# CC2756 register map
File version: 1.0
CPU: CM4 r0p4, little endian, no MPU, no FPU, VTOR, 3 interrupt priority bits
Registers are 32-bit, read-write, reset 0x0 unless marked. A register's access mark holds for its fields unless they carry their own. Offsets are from the block's base; [hi:lo] are bit positions; {n}, {i} and the like mark numbered series; 'fields as' and 'values as' point back to an identical list.

## LRFDRFE (part 2 of 2)
Base 0x40083000
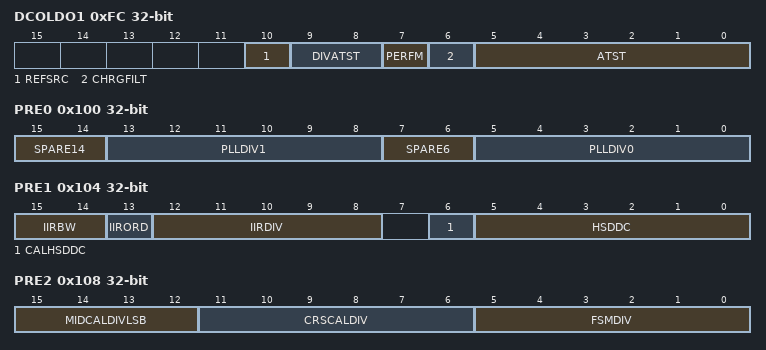
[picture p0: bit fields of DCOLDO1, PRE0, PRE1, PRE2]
0xFC DCOLDO1 — Internal. Only to be used through TI provided API.
  [10] REFSRC — Internal. Only to be used through TI provided API.
    1=BAW (Internal. Only to be used through TI provided API.); 0=XTAL (Internal. Only to be used through TI provided API.)
  [9:8] DIVATST — Internal. Only to be used through TI provided API.
    3=ONES (Internal. Only to be used through TI provided API.); 0=ZEROS (Internal. Only to be used through TI provided API.)
  [7] PERFM — Internal. Only to be used through TI provided API.
    1=EN (Internal. Only to be used through TI provided API.); 0=DIS (Internal. Only to be used through TI provided API.)
  [6] CHRGFILT — Internal. Only to be used through TI provided API.
    values as PERFM
  [5:0] ATST — Internal. Only to be used through TI provided API.
    32=VSSANA (Internal. Only to be used through TI provided API.); 1=FIRST_OUT (Internal. Only to be used through TI provided API.); 0=LDO_OUT (Internal. Only to be used through TI provided API.)
0x100 PRE0 — Internal. Only to be used through TI provided API.
  [15:14] SPARE14 — Internal. Only to be used through TI provided API.
    3=ALLONES (Internal. Only to be used through TI provided API.); 0=ALLZEROS (Internal. Only to be used through TI provided API.)
  [13:8] PLLDIV1 — Internal. Only to be used through TI provided API.
    63=ALLONES (Internal. Only to be used through TI provided API.); 0=ALLZEROS (Internal. Only to be used through TI provided API.)
  [7:6] SPARE6 — Internal. Only to be used through TI provided API.
    values as SPARE14
  [5:0] PLLDIV0 — Internal. Only to be used through TI provided API.
    values as PLLDIV1
0x104 PRE1 — Internal. Only to be used through TI provided API.
  [15:14] IIRBW — Internal. Only to be used through TI provided API.
    3=K16 (Internal. Only to be used through TI provided API.); 2=K8 (Internal. Only to be used through TI provided API.); 1=K4 (Internal. Only to be used through TI provided API.); 0=K2 (Internal. Only to be used through TI provided API.)
  [13] IIRORD — Internal. Only to be used through TI provided API.
    1=SECOND (Internal. Only to be used through TI provided API.); 0=FIRST (Internal. Only to be used through TI provided API.)
  [12:8] IIRDIV — Internal. Only to be used through TI provided API.
    31=ALLONES (Internal. Only to be used through TI provided API.); 0=ALLZEROS (Internal. Only to be used through TI provided API.)
  [6] CALHSDDC — Internal. Only to be used through TI provided API.
    1=GATE (Internal. Only to be used through TI provided API.); 0=NOGATE (Internal. Only to be used through TI provided API.)
  [5:0] HSDDC — Internal. Only to be used through TI provided API.
    values as PRE0.PLLDIV1
0x108 PRE2 — Internal. Only to be used through TI provided API.
  [15:12] MIDCALDIVLSB — Internal. Only to be used through TI provided API.
    15=ALLONES (Internal. Only to be used through TI provided API.); 0=ALLZEROS (Internal. Only to be used through TI provided API.)
  [11:6] CRSCALDIV — Internal. Only to be used through TI provided API.
    values as PRE0.PLLDIV1
  [5:0] FSMDIV — Internal. Only to be used through TI provided API.
    values as PRE0.PLLDIV1
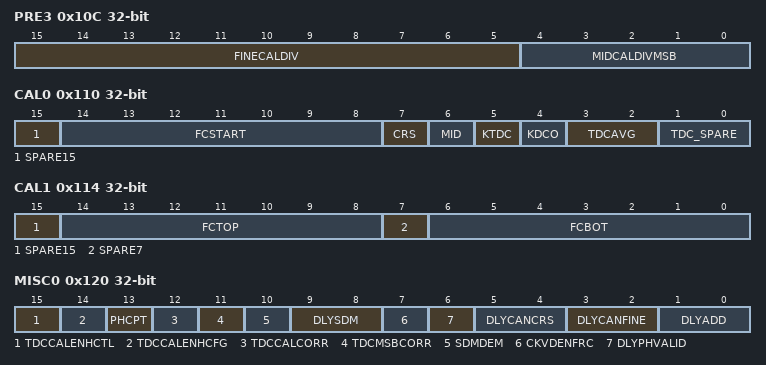
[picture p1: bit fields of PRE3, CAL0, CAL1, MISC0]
0x10C PRE3 — Internal. Only to be used through TI provided API.
  [15:5] FINECALDIV — Internal. Only to be used through TI provided API.
    0x7FF=ALLONES (Internal. Only to be used through TI provided API.); 0=ALLZEROS (Internal. Only to be used through TI provided API.)
  [4:0] MIDCALDIVMSB — Internal. Only to be used through TI provided API.
    values as PRE1.IIRDIV
0x110 CAL0 — Internal. Only to be used through TI provided API.
  [15] SPARE15 — Internal. Only to be used through TI provided API.
    1=ONE (Internal. Only to be used through TI provided API.); 0=ZERO (Internal. Only to be used through TI provided API.)
  [14:8] FCSTART — Internal. Only to be used through TI provided API.
    127=ALLONES (Internal. Only to be used through TI provided API.); 0=ALLZEROS (Internal. Only to be used through TI provided API.)
  [7] CRS — Internal. Only to be used through TI provided API.
    values as DCOLDO1.PERFM
  [6] MID — Internal. Only to be used through TI provided API.
    values as DCOLDO1.PERFM
  [5] KTDC — Internal. Only to be used through TI provided API.
    values as DCOLDO1.PERFM
  [4] KDCO — Internal. Only to be used through TI provided API.
    values as DCOLDO1.PERFM
  [3:2] TDCAVG — Internal. Only to be used through TI provided API.
    3=REPEAT_8_TIMES (Internal. Only to be used through TI provided API.); 2=REPEAT_4_TIMES (Internal. Only to be used through TI provided API.); 1=REPEAT_2_TIMES (Internal. Only to be used through TI provided API.); 0=REPEAT_1_TIME (Internal. Only to be used through TI provided API.)
  [1:0] TDC_SPARE — Internal. Only to be used through TI provided API.
    values as PRE0.SPARE14
0x114 CAL1 — Internal. Only to be used through TI provided API.
  [15] SPARE15 — Internal. Only to be used through TI provided API.
    values as CAL0.SPARE15
  [14:8] FCTOP — Internal. Only to be used through TI provided API.
    values as CAL0.FCSTART
  [7] SPARE7 — Internal. Only to be used through TI provided API.
    values as CAL0.SPARE15
  [6:0] FCBOT — Internal. Only to be used through TI provided API.
    values as CAL0.FCSTART
0x118 CAL2 — Internal. Only to be used through TI provided API.
  [15:0] KTDCINV
    0xFFFF=ALLONES (Internal. Only to be used through TI provided API.); 0=ALLZEROS (Internal. Only to be used through TI provided API.)
0x11C CAL3 — Internal. Only to be used through TI provided API.
  [15:0] DTXGAIN
    values as CAL2.KTDCINV
0x120 MISC0 — Internal. Only to be used through TI provided API.
  [15] TDCCALENHCTL — Internal. Only to be used through TI provided API.
    values as DCOLDO1.PERFM
  [14] TDCCALENHCFG — Internal. Only to be used through TI provided API.
    1=MAXOFFSET (Internal. Only to be used through TI provided API.); 0=MINOFFSET (Internal. Only to be used through TI provided API.)
  [13] PHCPT — Internal. Only to be used through TI provided API.
    1=ASYNC (Internal. Only to be used through TI provided API.); 0=SYNC (Internal. Only to be used through TI provided API.)
  [12] TDCCALCORR — Internal. Only to be used through TI provided API.
    values as DCOLDO1.PERFM
  [11] TDCMSBCORR — Internal. Only to be used through TI provided API.
    values as DCOLDO1.PERFM
  [10] SDMDEM — Internal. Only to be used through TI provided API.
    values as DCOLDO1.PERFM
  [9:8] DLYSDM — Internal. Only to be used through TI provided API.
    {v}=CKVD16_{v}_PER (Internal. Only to be used through TI provided API.) (v=0..3)
  [7] CKVDENFRC — Internal. Only to be used through TI provided API.
    values as DCOLDO1.PERFM
  [6] DLYPHVALID — Internal. Only to be used through TI provided API.
    1=NOQUAL (Internal. Only to be used through TI provided API.); 0=QUAL (Internal. Only to be used through TI provided API.)
  [5:4] DLYCANCRS — Internal. Only to be used through TI provided API.
    {v}=CKVD64_{v}_PER (Internal. Only to be used through TI provided API.) (v=0..3)
  [3:2] DLYCANFINE — Internal. Only to be used through TI provided API.
    {v}=CKVD16_{v+1}_PER (Internal. Only to be used through TI provided API.) (v=0..3)
  [1:0] DLYADD — Internal. Only to be used through TI provided API.
    values as DLYCANCRS
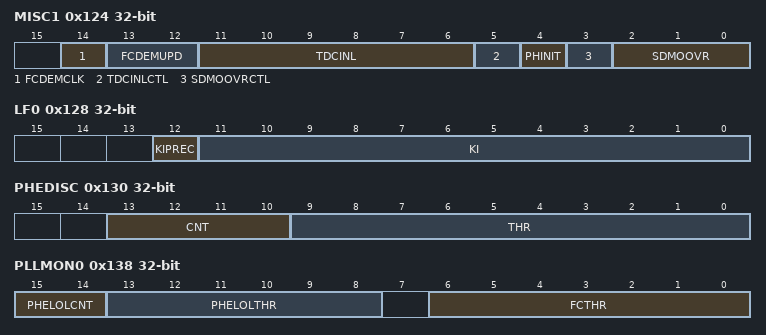
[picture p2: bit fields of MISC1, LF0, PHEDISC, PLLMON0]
0x124 MISC1 — Internal. Only to be used through TI provided API.
  [14] FCDEMCLK — Internal. Only to be used through TI provided API.
    1=CKVD64 (Internal. Only to be used through TI provided API.); 0=CKCD16 (Internal. Only to be used through TI provided API.)
  [13:12] FCDEMUPD — Internal. Only to be used through TI provided API.
    3=SDM_XOR_PH_ERR (Internal. Only to be used through TI provided API.); 2=SDM (Internal. Only to be used through TI provided API.); 1=PH_ERR (Internal. Only to be used through TI provided API.); 0=DEFAULT (Internal. Only to be used through TI provided API.)
  [11:6] TDCINL — Internal. Only to be used through TI provided API.
    63=ONES (Internal. Only to be used through TI provided API.); 0=ZEROS (Internal. Only to be used through TI provided API.)
  [5] TDCINLCTL — Internal. Only to be used through TI provided API.
    values as DCOLDO1.PERFM
  [4] PHINIT — Internal. Only to be used through TI provided API.
    1=UNKNOWN (Internal. Only to be used through TI provided API.); 0=KNOWN (Internal. Only to be used through TI provided API.)
  [3] SDMOOVRCTL — Internal. Only to be used through TI provided API.
    values as DCOLDO1.PERFM
  [2:0] SDMOOVR — Internal. Only to be used through TI provided API.
    7=ALLONES (Internal. Only to be used through TI provided API.); 0=ALLZEROS (Internal. Only to be used through TI provided API.)
0x128 LF0 — Internal. Only to be used through TI provided API.
  [12] KIPREC — Internal. Only to be used through TI provided API.
    1=HIGH (Internal. Only to be used through TI provided API.); 0=LOW (Internal. Only to be used through TI provided API.)
  [11:0] KI — Internal. Only to be used through TI provided API.
    0xFFF=ALLONES (Internal. Only to be used through TI provided API.); 0=ALLZEROS (Internal. Only to be used through TI provided API.)
0x12C LF1 — Internal. Only to be used through TI provided API.
  [13:0] KP
    0x3FFF=ALLONES (Internal. Only to be used through TI provided API.); 0=ALLZEROS (Internal. Only to be used through TI provided API.)
0x130 PHEDISC — Internal. Only to be used through TI provided API.
  [13:10] CNT — Internal. Only to be used through TI provided API.
    values as PRE2.MIDCALDIVLSB
  [9:0] THR — Internal. Only to be used through TI provided API.
    0x3FF=ALLONES (Internal. Only to be used through TI provided API.); 0=ALLZEROS (Internal. Only to be used through TI provided API.)
0x134 PHINIT — Internal. Only to be used through TI provided API.
  [7:0] OFF
    255=ALLONES (Internal. Only to be used through TI provided API.); 0=ALLZEROS (Internal. Only to be used through TI provided API.)
0x138 PLLMON0 — Internal. Only to be used through TI provided API.
  [15:14] PHELOLCNT — Internal. Only to be used through TI provided API.
    3=REFCLK_128_PER (Internal. Only to be used through TI provided API.); 2=REFCLK_64_PER (Internal. Only to be used through TI provided API.); 1=REFCLK_32_PER (Internal. Only to be used through TI provided API.); 0=REFCLK_16_PER (Internal. Only to be used through TI provided API.)
  [13:8] PHELOLTHR — Internal. Only to be used through TI provided API.
    values as PRE0.PLLDIV1
  [6:0] FCTHR — Internal. Only to be used through TI provided API.
    values as CAL0.FCSTART
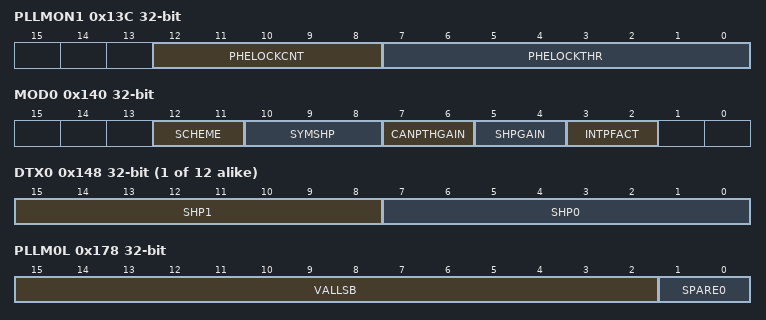
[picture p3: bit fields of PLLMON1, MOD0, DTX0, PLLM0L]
0x13C PLLMON1 — Internal. Only to be used through TI provided API.
  [12:8] PHELOCKCNT — Internal. Only to be used through TI provided API.
    values as PRE1.IIRDIV
  [7:0] PHELOCKTHR — Internal. Only to be used through TI provided API.
    values as PHINIT.OFF
0x140 MOD0 — Internal. Only to be used through TI provided API.
  [12:11] SCHEME — Internal. Only to be used through TI provided API.
    3=TWO_POINT_MOD_FRF (Internal. Only to be used through TI provided API.); 2=INLOOP_MOD_FRF (Internal. Only to be used through TI provided API.); 1=INLOOP_MOD_FREF (Internal. Only to be used through TI provided API.); 0=NC (Internal. Only to be used through TI provided API.)
  [10:8] SYMSHP — Internal. Only to be used through TI provided API.
    4=CHIRP (Internal. Only to be used through TI provided API.); 3=SHAPEDZIGBEE (Internal. Only to be used through TI provided API.); 2=PCWSPSK (Internal. Only to be used through TI provided API.); 1=ZIGBEE (Internal. Only to be used through TI provided API.); 0=SHAPEDFSK (Internal. Only to be used through TI provided API.)
  [7:6] CANPTHGAIN — Internal. Only to be used through TI provided API.
    {v}=TWO_POW_M_{v+15} (Internal. Only to be used through TI provided API.) (v=0..3)
  [5:4] SHPGAIN — Internal. Only to be used through TI provided API.
    3=X8 (Internal. Only to be used through TI provided API.); 2=X4 (Internal. Only to be used through TI provided API.); 1=X2 (Internal. Only to be used through TI provided API.); 0=Internal. Only to be used through TI provided API.
  [3:2] INTPFACT — Internal. Only to be used through TI provided API.
    3=ILLEGAL1 (Internal. Only to be used through TI provided API.); 2=INTP_BY_32 (Internal. Only to be used through TI provided API.); 1=INTP_BY_16 (Internal. Only to be used through TI provided API.); 0=ILLEGAL0 (Internal. Only to be used through TI provided API.)
0x144 MOD1 — Internal. Only to be used through TI provided API.
  [11:0] FOFF
    values as LF0.KI
{0x148+4i} DTX{i} (i=0..11) — Internal. Only to be used through TI provided API.
  [15:8] SHP{2i+1} — Internal. Only to be used through TI provided API.
    values as PHINIT.OFF
  [7:0] SHP{2i} — Internal. Only to be used through TI provided API.
    values as PHINIT.OFF
0x178 PLLM0L — Internal. Only to be used through TI provided API.
  [15:2] VALLSB — Internal. Only to be used through TI provided API.
    values as LF1.KP
  [1:0] SPARE0 — Internal. Only to be used through TI provided API.
    values as PRE0.SPARE14
0x17C PLLM0H — Internal. Only to be used through TI provided API.
  [15:0] VALMSB
    values as CAL2.KTDCINV
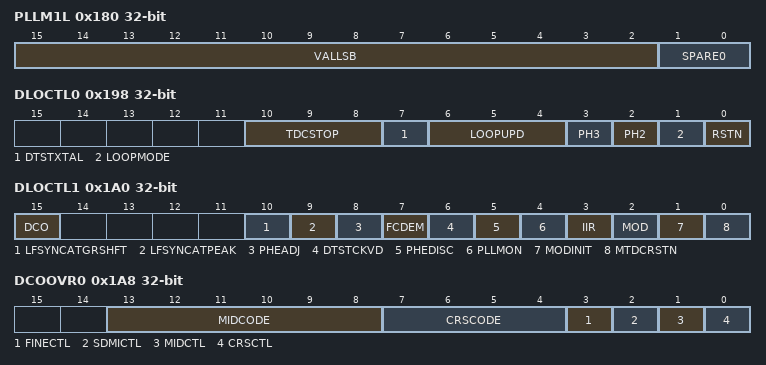
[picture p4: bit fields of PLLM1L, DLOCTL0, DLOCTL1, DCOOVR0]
0x180 PLLM1L — Internal. Only to be used through TI provided API.
  fields as PLLM0L
0x184 PLLM1H — Internal. Only to be used through TI provided API.
  fields as PLLM0H
0x188 CALMCRS — Internal. Only to be used through TI provided API.
  [15:0] VAL
    values as CAL2.KTDCINV
0x18C CALMMID — Internal. Only to be used through TI provided API.
  fields as CALMCRS
0x190 REFDIV — Internal. Only to be used through TI provided API.
  [15:0] LOAD
    values as CAL2.KTDCINV
0x198 DLOCTL0 — Internal. Only to be used through TI provided API.
  [10:8] TDCSTOP — Internal. Only to be used through TI provided API.
    1=OPEN (Internal. Only to be used through TI provided API.); 0=CLOSED (Internal. Only to be used through TI provided API.)
  [7] DTSTXTAL — Internal. Only to be used through TI provided API.
    values as CAL0.SPARE15
  [6:4] LOOPUPD — Internal. Only to be used through TI provided API.
    1=ALT (Internal. Only to be used through TI provided API.); 0=DEF (Internal. Only to be used through TI provided API.)
  [3] PH3 — Internal. Only to be used through TI provided API.
    1=START (Internal. Only to be used through TI provided API.); 0=HALT (Internal. Only to be used through TI provided API.)
  [2] PH2 — Internal. Only to be used through TI provided API.
    values as PH3
  [1] LOOPMODE — Internal. Only to be used through TI provided API.
    values as TDCSTOP
  [0] RSTN — Internal. Only to be used through TI provided API.
    1=ACTIVE (Internal. Only to be used through TI provided API.); 0=RESET (Internal. Only to be used through TI provided API.)
0x1A0 DLOCTL1 — Internal. Only to be used through TI provided API.
  [15] DCO — Internal. Only to be used through TI provided API.
    values as DCOLDO1.PERFM
  [10] LFSYNCATGRSHFT — Internal. Only to be used through TI provided API.
    values as DCOLDO1.PERFM
  [9] LFSYNCATPEAK — Internal. Only to be used through TI provided API.
    values as DCOLDO1.PERFM
  [8] PHEADJ — Internal. Only to be used through TI provided API.
    values as DCOLDO1.PERFM
  [7] FCDEM — Internal. Only to be used through TI provided API.
    values as DCOLDO1.PERFM
  [6] DTSTCKVD — Internal. Only to be used through TI provided API.
    values as CAL0.SPARE15
  [5] PHEDISC — Internal. Only to be used through TI provided API.
    values as DCOLDO1.PERFM
  [4] PLLMON — Internal. Only to be used through TI provided API.
    values as DCOLDO1.PERFM
  [3] IIR — Internal. Only to be used through TI provided API.
    values as DCOLDO1.PERFM
  [2] MOD — Internal. Only to be used through TI provided API.
    values as DCOLDO1.PERFM
  [1] MODINIT — Internal. Only to be used through TI provided API.
    1=ACTIVATE (Internal. Only to be used through TI provided API.); 0=DEACTIVATE (Internal. Only to be used through TI provided API.)
  [0] MTDCRSTN — Internal. Only to be used through TI provided API.
    values as DLOCTL0.RSTN
0x1A8 DCOOVR0 — Internal. Only to be used through TI provided API.
  [13:8] MIDCODE — Internal. Only to be used through TI provided API.
    values as PRE0.PLLDIV1
  [7:4] CRSCODE — Internal. Only to be used through TI provided API.
    values as PRE2.MIDCALDIVLSB
  [3] FINECTL — Internal. Only to be used through TI provided API.
    values as DCOLDO1.PERFM
  [2] SDMICTL — Internal. Only to be used through TI provided API.
    values as DCOLDO1.PERFM
  [1] MIDCTL — Internal. Only to be used through TI provided API.
    values as DCOLDO1.PERFM
  [0] CRSCTL — Internal. Only to be used through TI provided API.
    values as DCOLDO1.PERFM
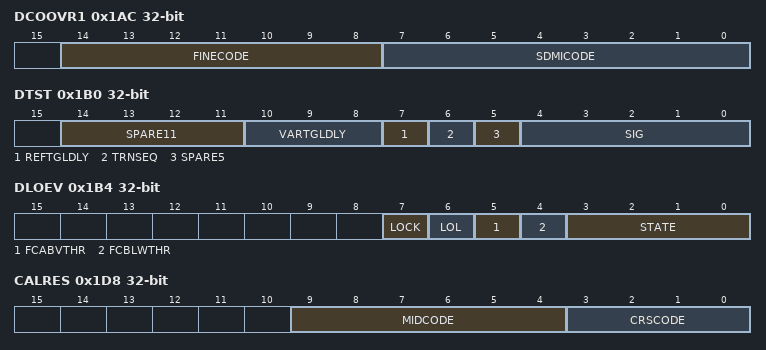
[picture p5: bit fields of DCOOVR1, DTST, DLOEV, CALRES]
0x1AC DCOOVR1 — Internal. Only to be used through TI provided API.
  [14:8] FINECODE — Internal. Only to be used through TI provided API.
    values as CAL0.FCSTART
  [7:0] SDMICODE — Internal. Only to be used through TI provided API.
    values as PHINIT.OFF
0x1B0 DTST — Internal. Only to be used through TI provided API.
  [14:11] SPARE11 — Internal. Only to be used through TI provided API.
    values as PRE2.MIDCALDIVLSB
  [10:8] VARTGLDLY — Internal. Only to be used through TI provided API.
    {v}=CLK_{v}_PER (Internal. Only to be used through TI provided API.) (v=0..7)
  [7] REFTGLDLY — Internal. Only to be used through TI provided API.
    1=CLK_1_PER (Internal. Only to be used through TI provided API.); 0=CLK_0_PER (Internal. Only to be used through TI provided API.)
  [6] TRNSEQ — Internal. Only to be used through TI provided API.
    values as DCOLDO1.PERFM
  [5] SPARE5 — Internal. Only to be used through TI provided API.
    values as CAL0.SPARE15
  [4:0] SIG — Internal. Only to be used through TI provided API.
    31=VAR_NC_15 (Internal. Only to be used through TI provided API.); 30=VAR_NC_14 (Internal. Only to be used through TI provided API.); 29=VAR_NC_13 (Internal. Only to be used through TI provided API.); 28=VAR_FCPHELFSYNC (Internal. Only to be used through TI provided API.); 27=VAR_FCPHE (Internal. Only to be used through TI provided API.); 26=VAR_LOOP_UPD_FINECODE (Internal. Only to be used through TI provided API.); 25=VAR_LOCK_FINECODE (Internal. Only to be used through TI provided API.); 24=VAR_MPX_CAN (Internal. Only to be used through TI provided API.); 23=VAR_TDCSTOP_STATUS_TDC (Internal. Only to be used through TI provided API.); 22=VAR_TDCSTOP_PHERR (Internal. Only to be used through TI provided API.); 21=VAR_PH_COMP_PHERR_TDCSTOP (Internal. Only to be used through TI provided API.); 20=VAR_PH_TDCCORR (Internal. Only to be used through TI provided API.); 19=VAR_PH_RAW (Internal. Only to be used through TI provided API.); 18=VAR_PHERR_LOWER (Internal. Only to be used through TI provided API.); 17=VAR_PHERR_UPPER (Internal. Only to be used through TI provided API.); 16=VAR_NC_0 (Internal. Only to be used through TI provided API.); {v}=REF_NC_{v} (Internal. Only to be used through TI provided API.) (v=3..15); 2=REF_FERR_MAG (Internal. Only to be used through TI provided API.); 1=REF_FSMCAL (Internal. Only to be used through TI provided API.); 0=REF_NC_0 (Internal. Only to be used through TI provided API.)
0x1B4 DLOEV ro — Internal. Only to be used through TI provided API.
  [7] LOCK — Internal. Only to be used through TI provided API.
    values as CAL0.SPARE15
  [6] LOL — Internal. Only to be used through TI provided API.
    values as CAL0.SPARE15
  [5] FCABVTHR — Internal. Only to be used through TI provided API.
    values as CAL0.SPARE15
  [4] FCBLWTHR — Internal. Only to be used through TI provided API.
    values as CAL0.SPARE15
  [3:0] STATE — Internal. Only to be used through TI provided API.
    values as PRE2.MIDCALDIVLSB
0x1B8 DTSTRD ro — Internal. Only to be used through TI provided API.
  [15:0] DATA
    values as CAL2.KTDCINV
0x1C0 FDCOSPANLSB ro — Internal. Only to be used through TI provided API.
  fields as CALMCRS
0x1C4 FDCOSPANMSB ro — Internal. Only to be used through TI provided API.
  [2:0] VAL
    values as MISC1.SDMOOVR
0x1C8 TDCCAL ro — Internal. Only to be used through TI provided API.
  fields as CALMCRS
0x1CC TDCCALLOW ro — Internal. Only to be used through TI provided API.
  fields as CALMCRS
0x1D0 TDCCALHIGH ro — Internal. Only to be used through TI provided API.
  fields as CALMCRS
0x1D4 TDCODET ro — Internal. Only to be used through TI provided API.
  [2:0] FLAGS
    values as MISC1.SDMOOVR
0x1D8 CALRES ro — Internal. Only to be used through TI provided API.
  [9:4] MIDCODE — Internal. Only to be used through TI provided API.
    values as PRE0.PLLDIV1
  [3:0] CRSCODE — Internal. Only to be used through TI provided API.
    values as PRE2.MIDCALDIVLSB
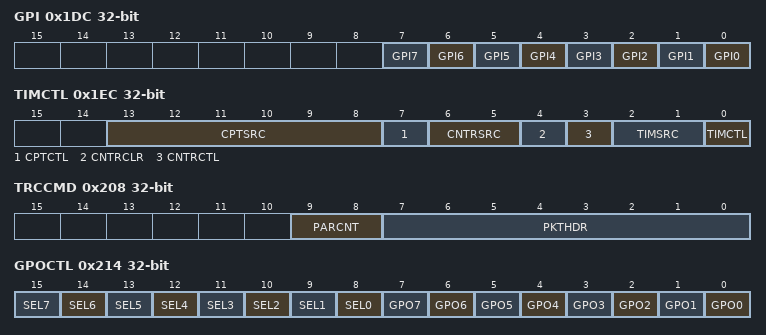
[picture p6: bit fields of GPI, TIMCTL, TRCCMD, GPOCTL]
0x1DC GPI ro — Internal. Only to be used through TI provided API.
  [all] fields
    values as CAL0.SPARE15
  [n] GPI{n} (n=0..7) — Internal. Only to be used through TI provided API.
0x1E0 MATHACCELIN — Internal. Only to be used through TI provided API.
  fields as CALMCRS
0x1E4 LIN2LOGOUT ro — Internal. Only to be used through TI provided API.
  [6:0] LOGVAL
    values as CAL0.FCSTART
0x1E8 DIVBY3OUT ro — Internal. Only to be used through TI provided API.
  [3:0] DIV3
    values as PRE2.MIDCALDIVLSB
0x1EC TIMCTL — Internal. Only to be used through TI provided API.
  [13:8] CPTSRC — Internal. Only to be used through TI provided API.
    values as PRE0.PLLDIV1
  [7] CPTCTL — Internal. Only to be used through TI provided API.
    values as DCOLDO1.PERFM
  [6:5] CNTRSRC — Internal. Only to be used through TI provided API.
    3=FREF (Internal. Only to be used through TI provided API.); 2=MAGN1 (Internal. Only to be used through TI provided API.); 1=MAGN0 (Internal. Only to be used through TI provided API.); 0=CLK (Internal. Only to be used through TI provided API.)
  [4] CNTRCLR — Internal. Only to be used through TI provided API.
    values as CAL0.SPARE15
  [3] CNTRCTL — Internal. Only to be used through TI provided API.
    values as DCOLDO1.PERFM
  [2:1] TIMSRC — Internal. Only to be used through TI provided API.
    values as CNTRSRC
  [0] TIMCTL — Internal. Only to be used through TI provided API.
    values as DCOLDO1.PERFM
0x1F0 TIMINC — Internal. Only to be used through TI provided API.
  fields as CALMCRS
0x1F4 TIMPER — Internal. Only to be used through TI provided API.
  fields as CALMCRS
0x1F8 TIMCNT ro — Internal. Only to be used through TI provided API.
  fields as CALMCRS
0x1FC TIMCAPT ro — Internal. Only to be used through TI provided API.
  [15:0] VALUE
    values as CAL2.KTDCINV
0x200 TRCCTRL wo — Internal. Only to be used through TI provided API.
  [0] SEND
    values as CAL0.SPARE15
0x204 TRCSTAT ro — Internal. Only to be used through TI provided API.
  [0] BUSY
    values as CAL0.SPARE15
0x208 TRCCMD — Internal. Only to be used through TI provided API.
  [9:8] PARCNT — Internal. Only to be used through TI provided API.
    values as PRE0.SPARE14
  [7:0] PKTHDR — Internal. Only to be used through TI provided API.
    values as PHINIT.OFF
0x20C TRCPAR0 — Internal. Only to be used through TI provided API.
  fields as CALMCRS
0x210 TRCPAR1 — Internal. Only to be used through TI provided API.
  fields as CALMCRS
0x214 GPOCTL — Internal. Only to be used through TI provided API.
  [n+8] SEL{n} (n=0..7) — Internal. Only to be used through TI provided API.
    1=HW (Internal. Only to be used through TI provided API.); 0=SW (Internal. Only to be used through TI provided API.)
  [n] GPO{n} (n=0..7) — Internal. Only to be used through TI provided API.
    values as CAL0.SPARE15
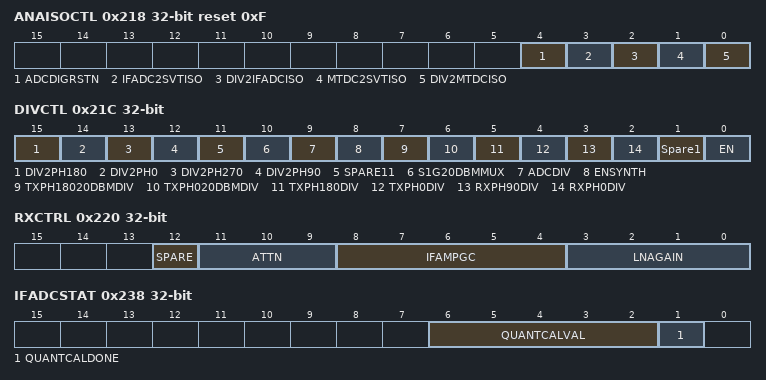
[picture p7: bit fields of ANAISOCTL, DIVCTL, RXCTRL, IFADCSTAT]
0x218 ANAISOCTL reset 0xF — Internal. Only to be used through TI provided API.
  [4] ADCDIGRSTN — Internal. Only to be used through TI provided API.
    values as DLOCTL0.RSTN
  [3] IFADC2SVTISO — Internal. Only to be used through TI provided API.
    1=ISOLATE (Internal. Only to be used through TI provided API.); 0=CONNECT (Internal. Only to be used through TI provided API.)
  [2] DIV2IFADCISO — Internal. Only to be used through TI provided API.
    values as IFADC2SVTISO
  [1] MTDC2SVTISO — Internal. Only to be used through TI provided API.
    values as IFADC2SVTISO
  [0] DIV2MTDCISO — Internal. Only to be used through TI provided API.
    values as IFADC2SVTISO
0x21C DIVCTL — Internal. Only to be used through TI provided API.
  [15] DIV2PH180 — Internal. Only to be used through TI provided API.
    values as DCOLDO1.PERFM
  [14] DIV2PH0 — Internal. Only to be used through TI provided API.
    values as DCOLDO1.PERFM
  [13] DIV2PH270 — Internal. Only to be used through TI provided API.
    values as DCOLDO1.PERFM
  [12] DIV2PH90 — Internal. Only to be used through TI provided API.
    values as DCOLDO1.PERFM
  [11] SPARE11 — Internal. Only to be used through TI provided API.
    values as CAL0.SPARE15
  [10] S1G20DBMMUX — Internal. Only to be used through TI provided API.
    1=DISABLE (Internal. Only to be used through TI provided API.); 0=ENABLEN (Internal. Only to be used through TI provided API.)
  [9] ADCDIV — Internal. Only to be used through TI provided API.
    values as DCOLDO1.PERFM
  [8] ENSYNTH — Internal. Only to be used through TI provided API.
    values as DCOLDO1.PERFM
  [7] TXPH18020DBMDIV — Internal. Only to be used through TI provided API.
    values as DCOLDO1.PERFM
  [6] TXPH020DBMDIV — Internal. Only to be used through TI provided API.
    values as DCOLDO1.PERFM
  [5] TXPH180DIV — Internal. Only to be used through TI provided API.
    values as DCOLDO1.PERFM
  [4] TXPH0DIV — Internal. Only to be used through TI provided API.
    values as DCOLDO1.PERFM
  [3] RXPH90DIV — Internal. Only to be used through TI provided API.
    values as DCOLDO1.PERFM
  [2] RXPH0DIV — Internal. Only to be used through TI provided API.
    values as DCOLDO1.PERFM
  [1] Spare1 — Internal. Only to be used through TI provided API.
    values as CAL0.SPARE15
  [0] EN — Internal. Only to be used through TI provided API.
    1=ON (Internal. Only to be used through TI provided API.); 0=OFF (Internal. Only to be used through TI provided API.)
0x220 RXCTRL — Internal. Only to be used through TI provided API.
  [12] SPARE — Internal. Only to be used through TI provided API.
    values as CAL0.SPARE15
  [11:9] ATTN — Internal. Only to be used through TI provided API.
    7=_21DB (Internal. Only to be used through TI provided API.); 6=_18DB (Internal. Only to be used through TI provided API.); 5=_15DB (Internal. Only to be used through TI provided API.); 4=_12DB (Internal. Only to be used through TI provided API.); 3=_9DB (Internal. Only to be used through TI provided API.); 2=_6DB (Internal. Only to be used through TI provided API.); 1=_3DB (Internal. Only to be used through TI provided API.); 0=NOATT (Internal. Only to be used through TI provided API.)
  [8:4] IFAMPGC — Internal. Only to be used through TI provided API.
    31=MAX (Internal. Only to be used through TI provided API.); 15=MIN3DB (Internal. Only to be used through TI provided API.); 7=MIN6DB (Internal. Only to be used through TI provided API.); 3=MIN9DB (Internal. Only to be used through TI provided API.); 1=MIN12DB (Internal. Only to be used through TI provided API.); 0=MIN15DB (Internal. Only to be used through TI provided API.)
  [3:0] LNAGAIN — Internal. Only to be used through TI provided API.
    15=MAX (Internal. Only to be used through TI provided API.); 7=MIN3DB (Internal. Only to be used through TI provided API.); 3=MIN6DB (Internal. Only to be used through TI provided API.); 1=MIN9DB (Internal. Only to be used through TI provided API.); 0=MIN12DB (Internal. Only to be used through TI provided API.)
0x224 MAGNACC0 ro — Internal. Only to be used through TI provided API.
  fields as CALMCRS
0x228 MAGNACC1 ro — Internal. Only to be used through TI provided API.
  fields as CALMCRS
0x22C RSSI — Internal. Only to be used through TI provided API.
  [7:0] VAL
    values as PHINIT.OFF
0x230 RSSIMAX — Internal. Only to be used through TI provided API.
  fields as RSSI
0x234 RFGAIN — Internal. Only to be used through TI provided API.
  [7:0] DBGAIN
    values as PHINIT.OFF
0x238 IFADCSTAT ro — Internal. Only to be used through TI provided API.
  [6:2] QUANTCALVAL — Internal. Only to be used through TI provided API.
    1=COMP1 (Internal. Only to be used through TI provided API.); 0=COMP0 (Internal. Only to be used through TI provided API.)
  [1] QUANTCALDONE — Internal. Only to be used through TI provided API.
    1=READY (Internal. Only to be used through TI provided API.); 0=NOT_READY (Internal. Only to be used through TI provided API.)
0x23C DIVSTA ro — Internal. Only to be used through TI provided API.
  [0] STAT
    1=BUSY (Internal. Only to be used through TI provided API.); 0=IDLE (Internal. Only to be used through TI provided API.)
0x240 DIVIDENDL wo — Internal. Only to be used through TI provided API.
  [15:0] VALLSB
    values as CAL2.KTDCINV
0x244 DIVIDENDH wo — Internal. Only to be used through TI provided API.
  fields as PLLM0H
0x248 DIVISORL — Internal. Only to be used through TI provided API.
  fields as DIVIDENDL
0x24C DIVISORH — Internal. Only to be used through TI provided API.
  fields as PLLM0H
0x250 QUOTIENTL ro — Internal. Only to be used through TI provided API.
  fields as DIVIDENDL
0x254 QUOTIENTH ro — Internal. Only to be used through TI provided API.
  fields as PLLM0H
0x258 PRODUCTL ro — Internal. Only to be used through TI provided API.
  fields as DIVIDENDL
0x25C PRODUCTH ro — Internal. Only to be used through TI provided API.
  fields as PLLM0H
0x260 MULTSTA ro — Internal. Only to be used through TI provided API.
  fields as DIVSTA
0x268 MULTCFG — Internal. Only to be used through TI provided API.
  [0] MODE
    1=SIGNED (Internal. Only to be used through TI provided API.); 0=UNSIGNED (Internal. Only to be used through TI provided API.)
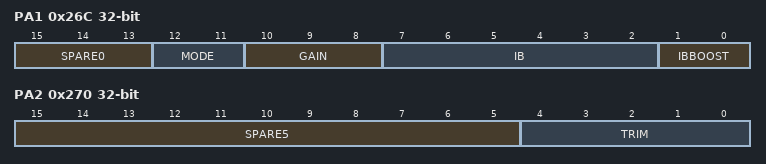
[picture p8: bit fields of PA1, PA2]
0x26C PA1 — Internal. Only to be used through TI provided API.
  [15:13] SPARE0 — Internal. Only to be used through TI provided API.
    7=MAX (Internal. Only to be used through TI provided API.); 0=MIN (Internal. Only to be used through TI provided API.)
  [12:11] MODE — Internal. Only to be used through TI provided API.
    3=DBM20 (Internal. Only to be used through TI provided API.); 2=DBM12 (Internal. Only to be used through TI provided API.); 1=DBM5 (Internal. Only to be used through TI provided API.); 0=DBM0 (Internal. Only to be used through TI provided API.)
  [10:8] GAIN — Internal. Only to be used through TI provided API.
    values as SPARE0
  [7:2] IB — Internal. Only to be used through TI provided API.
    63=MAX (Internal. Only to be used through TI provided API.); 0=MIN (Internal. Only to be used through TI provided API.)
  [1:0] IBBOOST — Internal. Only to be used through TI provided API.
    3=MAX (Internal. Only to be used through TI provided API.); 0=MIN (Internal. Only to be used through TI provided API.)
0x270 PA2 — Internal. Only to be used through TI provided API.
  [15:5] SPARE5 — Internal. Only to be used through TI provided API.
    0x7FF=MAX (Internal. Only to be used through TI provided API.); 0=MIN (Internal. Only to be used through TI provided API.)
  [4:0] TRIM — Internal. Only to be used through TI provided API.
    31=MAX (Internal. Only to be used through TI provided API.); 0=MIN (Internal. Only to be used through TI provided API.)
